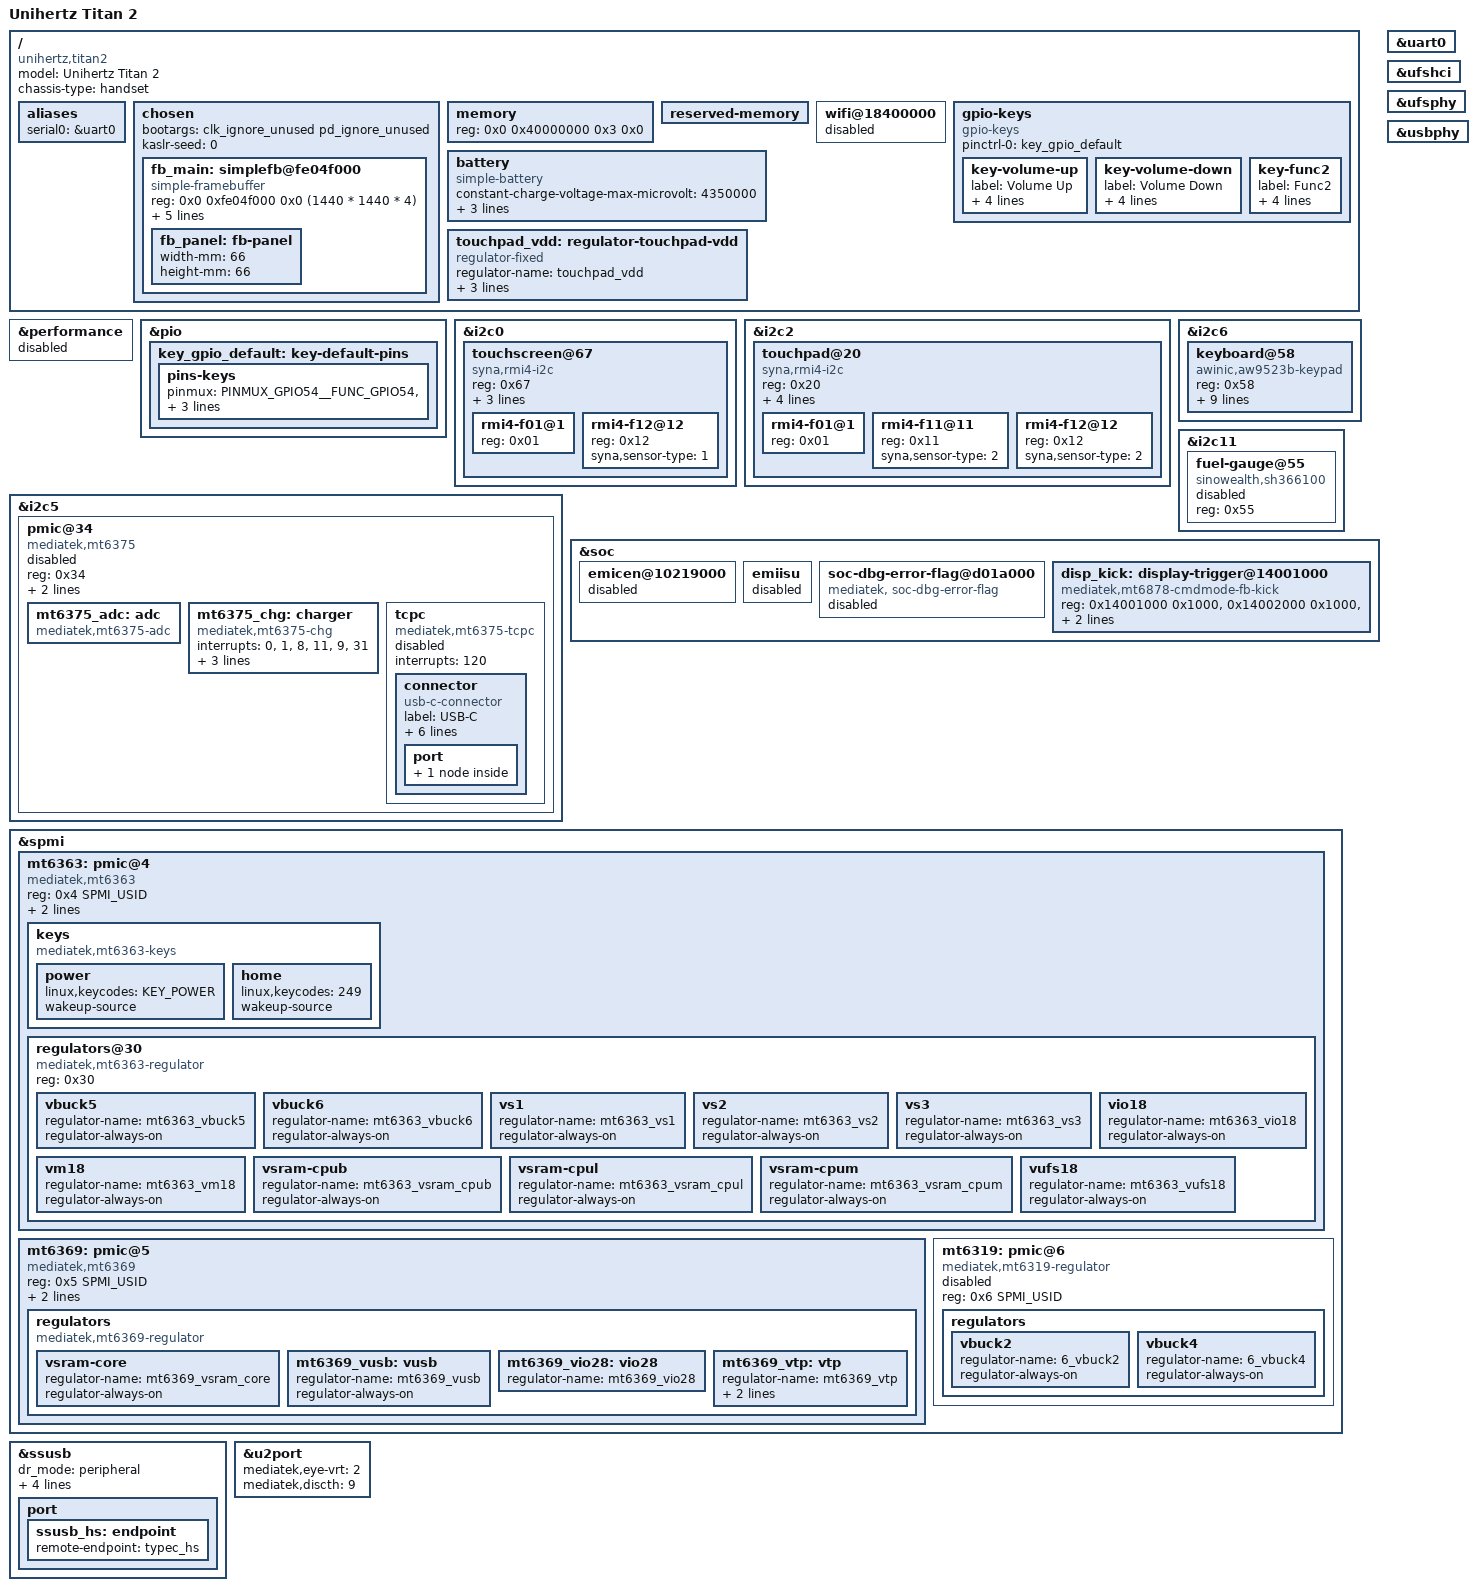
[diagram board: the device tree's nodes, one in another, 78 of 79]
// SPDX-License-Identifier: (GPL-2.0-only OR MIT)
/*
 * Unihertz Titan 2 (MediaTek MT6878 / Dimensity 7300)
 *
 * Copyright (c) 2026 serlk <22211586+Serlk@users.noreply.github.com>
 *
 * Booted by the stock LK from slot B; LK fills /chosen, memory and the
 * reserved-memory carveouts at boot. Values below are from the DT the
 * stock LK passes to Android (V01.00.14).
 */

/dts-v1/;
#include "mt6878.dtsi"
#include <dt-bindings/gpio/gpio.h>
#include <dt-bindings/iio/adc/mediatek,mt6375-adc.h>
#include <dt-bindings/input/input.h>
#include <dt-bindings/interrupt-controller/irq.h>
#include <dt-bindings/spmi/spmi.h>
#include <dt-bindings/usb/pd.h>

/ {
	model = "Unihertz Titan 2";
	chassis-type = "handset";
	compatible = "unihertz,titan2", "mediatek,mt6878";

	#address-cells = <2>;
	#size-cells = <2>;

	aliases {
		serial0 = &uart0;
	};

	chosen {
		bootargs = "clk_ignore_unused pd_ignore_unused";
		/* LK fills it from its TRNG, but only when the property exists */
		kaslr-seed = /bits/ 64 <0>;
		#address-cells = <2>;
		#size-cells = <2>;
		ranges;

		/*
		 * Main display (A61QWERTY46, 1440x1440) as left by LK:
		 * atag,videolfb fb_base 0xfe04f000, 59.92 Hz. Format and stride
		 * still to be confirmed on the device.
		 */
		fb_main: simplefb@fe04f000 {
			compatible = "simple-framebuffer";
			reg = <0x0 0xfe04f000 0x0 (1440 * 1440 * 4)>;
			width = <1440>;
			height = <1440>;
			stride = <(1440 * 4)>;
			format = "a8r8g8b8";
			panel = <&fb_panel>;

			fb_panel: fb-panel {
				width-mm = <66>;
				height-mm = <66>;
			};
		};
	};

	memory {
		device_type = "memory";
		/* 12 GiB; LK rewrites this node */
		reg = <0x0 0x40000000 0x3 0x0>;
	};

	/*
	 * The stock LK adds ~47 mblock-* carveouts here itself (ATF, TEE, modem,
	 * pstore, framebuffer, ...); static entries would overlap them. Start
	 * from an empty node instead of the SoC's static list.
	 */
	/delete-node/ reserved-memory;
	reserved-memory {
		#address-cells = <2>;
		#size-cells = <2>;
		ranges;
	};

	/*
	 * Nodes the stock LK requires when it completes the device tree
	 * (titan2-docs: docs/lk-boot-requirements.md);
	 * without them LK asserts or panics before starting the kernel.
	 * LK writes the Wi-Fi carveout into /wifi as memory-region.
	 */
	wifi@18400000 {
		status = "disabled";
	};

	gpio-keys {
		compatible = "gpio-keys";
		pinctrl-0 = <&key_gpio_default>;
		pinctrl-names = "default";

		key-volume-up {
			label = "Volume Up";
			linux,code = <KEY_VOLUMEUP>;
			gpios = <&pio 54 GPIO_ACTIVE_LOW>;
			debounce-interval = <30>;
			wakeup-source;
		};

		key-volume-down {
			label = "Volume Down";
			linux,code = <KEY_VOLUMEDOWN>;
			gpios = <&pio 55 GPIO_ACTIVE_LOW>;
			debounce-interval = <30>;
			wakeup-source;
		};

		/*
		 * Programmable side key "Func2" (as the GPL v2 module gpio_key.ko
		 * shipped with Titan 2 V01.00.14: GPIO73,
		 * both edges, low = pressed, scan code 250, 200 us EINT debounce).
		 */
		key-func2 {
			label = "Func2";
			linux,code = <250>;
			gpios = <&pio 73 GPIO_ACTIVE_LOW>;
			debounce-interval = <10>;
			wakeup-source;
		};
	};

	/*
	 * Li-ion pack (titan2-docs: docs/hardware). The charge voltage is the
	 * stock one: mtk_charger battery_cv 4.45 V, the MT6375 CV field reads
	 * 0x37 (4450 mV) in stock runtime logs. The current is a first-stage
	 * cap, below the stock 1.2 A (SDP) / 2.05 A (DCP); termination and
	 * the 0..50 degC charging window are the stock DT values.
	 *
	 * First stage: 4.35 V, what LK itself programs before the kernel, until
	 * charging has been watched on the device; the stock 4.45 V comes later.
	 */
	battery: battery {
		compatible = "simple-battery";
		constant-charge-voltage-max-microvolt = <4350000>;
		constant-charge-current-max-microamp = <1000000>;
		charge-term-current-microamp = <300000>;
		operating-range-celsius = <0 50>;
	};

	/*
	 * Power switch of the keyboard touchpad (stock touch_pad,pwr-gpio,
	 * GPIO59, high = on; the touchpad's GPL module of Titan 2 V01.00.14
	 * waits 20 ms before reset).
	 */
	touchpad_vdd: regulator-touchpad-vdd {
		compatible = "regulator-fixed";
		regulator-name = "touchpad_vdd";
		gpio = <&pio 59 GPIO_ACTIVE_HIGH>;
		enable-active-high;
		startup-delay-us = <20000>;
	};
};

/*
 * CPU DVFS stays with the frequencies LK left until it has been seen
 * working on the device: see mt6878-unihertz-titan2-dvfs.dts.
 */
&performance {
	status = "disabled";
};

&pio {
	key_gpio_default: key-default-pins {
		pins-keys {
			pinmux = <PINMUX_GPIO54__FUNC_GPIO54>,
				 <PINMUX_GPIO55__FUNC_GPIO55>;
			input-enable;
			bias-pull-up;
		};
	};
};

/*
 * Input devices from the stock DT (titan2-docs: docs/hardware). The keyboard and the
 * touchscreen take their supplies from the MT6369 on SPMI; a board without
 * SPMI has to disable them together with it.
 */

/*
 * Main touchscreen: Synaptics DSX/RMI4 (F12); facts from the GPL module
 * synaptics_tp.ko shipped with Titan 2 V01.00.14
 */
&i2c0 {
	#address-cells = <1>;
	#size-cells = <0>;

	/* The stock DT runs this bus at 400 kHz */
	touchscreen@67 {
		compatible = "syna,rmi4-i2c";
		reg = <0x67>;
		interrupts-extended = <&pio 7 IRQ_TYPE_LEVEL_LOW>;
		/* GPIO6 is routed as touch,reset-gpio but the factory driver never drives it */
		vdd-supply = <&mt6369_vtp>;
		syna,startup-delay-ms = <100>;

		#address-cells = <1>;
		#size-cells = <0>;

		rmi4-f01@1 {
			reg = <0x01>;
		};

		rmi4-f12@12 {
			reg = <0x12>;
			syna,sensor-type = <1>;
		};
	};
};

/*
 * Keyboard touchpad: Synaptics S1403, RMI4 (F11); facts from the GPL module
 * synaptics_1403_touch.ko shipped with Titan 2 V01.00.14
 */
&i2c2 {
	#address-cells = <1>;
	#size-cells = <0>;

	touchpad@20 {
		compatible = "syna,rmi4-i2c";
		reg = <0x20>;
		interrupts-extended = <&pio 75 IRQ_TYPE_LEVEL_LOW>;
		reset-gpios = <&pio 4 GPIO_ACTIVE_LOW>;
		vdd-supply = <&touchpad_vdd>;
		syna,reset-delay-ms = <120>;

		#address-cells = <1>;
		#size-cells = <0>;

		rmi4-f01@1 {
			reg = <0x01>;
		};

		rmi4-f11@11 {
			reg = <0x11>;
			syna,sensor-type = <2>;
		};

		rmi4-f12@12 {
			reg = <0x12>;
			syna,sensor-type = <2>;
		};
	};
};

/*
 * QWERTY keyboard: matrix on an AW9523B expander; facts from the GPL module
 * aw9523_key.ko shipped with Titan 2 V01.00.14
 */
&i2c6 {
	keyboard@58 {
		compatible = "awinic,aw9523b-keypad";
		reg = <0x58>;
		interrupts-extended = <&pio 12 IRQ_TYPE_LEVEL_LOW>;
		reset-gpios = <&pio 53 GPIO_ACTIVE_LOW>;
		vio-supply = <&mt6369_vio28>;
		label = "TitanKey";
		/* Stock input_port_mask 0x1ff and output_port_mask 0xfe00 */
		awinic,row-lines = <0 1 2 3 4 5 6 7 8>;
		awinic,column-lines = <9 10 11 12 13 14 15>;
		wakeup-source;

		/*
		 * The stock key_map[] as is: entry 7 * row + column. Duplicates and
		 * the F1/F10/F11/F13/arrows/VOLUMEUP/STOP..FIND entries probably have
		 * no key behind them. 251 is Fn, 253 Sym; Alt (KEY_RIGHTALT) is the
		 * only key on row 8, the stock "Alt wakes the screen" line.
		 */
		linux,keymap = <
					MATRIX_KEY(0, 0, KEY_Y)	/* 0 Y */
					MATRIX_KEY(0, 1, KEY_T)	/* 1 T */
					MATRIX_KEY(0, 2, KEY_G)	/* 2 G */
					MATRIX_KEY(0, 3, KEY_H)	/* 3 H */
					MATRIX_KEY(0, 4, KEY_SPACE)	/* 4 Space */
					MATRIX_KEY(0, 5, KEY_B)	/* 5 B */
					MATRIX_KEY(0, 6, KEY_F1)	/* 6 F1 */
					MATRIX_KEY(1, 0, KEY_U)	/* 7 U */
					MATRIX_KEY(1, 1, KEY_R)	/* 8 R */
					MATRIX_KEY(1, 2, KEY_F)	/* 9 F */
					MATRIX_KEY(1, 3, KEY_J)	/* 10 J */
					MATRIX_KEY(1, 4, KEY_V)	/* 11 V */
					MATRIX_KEY(1, 5, KEY_N)	/* 12 N */
					MATRIX_KEY(1, 6, KEY_U)	/* 13 U */
					MATRIX_KEY(2, 0, KEY_I)	/* 14 I */
					MATRIX_KEY(2, 1, KEY_E)	/* 15 E */
					MATRIX_KEY(2, 2, KEY_D)	/* 16 D */
					MATRIX_KEY(2, 3, KEY_K)	/* 17 K */
					MATRIX_KEY(2, 4, KEY_C)	/* 18 C */
					MATRIX_KEY(2, 5, KEY_M)	/* 19 M */
					MATRIX_KEY(2, 6, KEY_K)	/* 20 K */
					MATRIX_KEY(3, 0, KEY_O)	/* 21 O */
					MATRIX_KEY(3, 1, KEY_W)	/* 22 W */
					MATRIX_KEY(3, 2, KEY_S)	/* 23 S */
					MATRIX_KEY(3, 3, KEY_L)	/* 24 L */
					MATRIX_KEY(3, 4, KEY_X)	/* 25 X */
					MATRIX_KEY(3, 5, KEY_ENTER)	/* 26 ENTER */
					MATRIX_KEY(3, 6, KEY_F)	/* 27 F */
					MATRIX_KEY(4, 0, KEY_P)	/* 28 P */
					MATRIX_KEY(4, 1, KEY_Q)	/* 29 Q */
					MATRIX_KEY(4, 2, KEY_A)	/* 30 A */
					MATRIX_KEY(4, 3, KEY_BACKSPACE)	/* 31 DEL */
					MATRIX_KEY(4, 4, KEY_Z)	/* 32 Z */
					MATRIX_KEY(4, 5, KEY_Z)	/* 33 Z */
					MATRIX_KEY(4, 6, KEY_X)	/* 34 X */
					MATRIX_KEY(5, 0, KEY_LEFTSHIFT)	/* 35 SHIFT-L */
					MATRIX_KEY(5, 1, 253)	/* 36 AGUI_SYM */
					MATRIX_KEY(5, 2, KEY_BACK)	/* 37 BACK */
					MATRIX_KEY(5, 3, KEY_APPSELECT)	/* 38 MENU */
					MATRIX_KEY(5, 4, KEY_F10)	/* 39 F10 */
					MATRIX_KEY(5, 5, KEY_N)	/* 40 N */
					MATRIX_KEY(5, 6, KEY_M)	/* 41 M */
					MATRIX_KEY(6, 0, 251)	/* 42 FUNC3 */
					MATRIX_KEY(6, 1, KEY_DOWN)	/* 43 Down */
					MATRIX_KEY(6, 2, KEY_UP)	/* 44 Up */
					MATRIX_KEY(6, 3, KEY_ENTER)	/* 45 ENTER */
					MATRIX_KEY(6, 4, KEY_F11)	/* 46 F11 */
					MATRIX_KEY(6, 5, KEY_F13)	/* 47 F13 */
					MATRIX_KEY(6, 6, KEY_ALTERASE)	/* 48 ALT */
					MATRIX_KEY(7, 0, KEY_DOT)	/* 49 . */
					MATRIX_KEY(7, 1, KEY_LEFT)	/* 50 Left */
					MATRIX_KEY(7, 2, KEY_RIGHT)	/* 51 Right */
					MATRIX_KEY(7, 3, KEY_SPACE)	/* 52 Space */
					MATRIX_KEY(7, 4, KEY_VOLUMEUP)	/* 53 Volup */
					MATRIX_KEY(7, 5, KEY_STOP)	/* 54 KEY_STOP */
					MATRIX_KEY(7, 6, KEY_AGAIN)	/* 55 KEY_AGAIN */
					MATRIX_KEY(8, 0, KEY_RIGHTALT)	/* 56 SYM */
					MATRIX_KEY(8, 1, KEY_UNDO)	/* 57 UNDO */
					MATRIX_KEY(8, 2, KEY_FRONT)	/* 58 FRONT */
					MATRIX_KEY(8, 3, KEY_COPY)	/* 59 COPY */
					MATRIX_KEY(8, 4, KEY_OPEN)	/* 60 OPEN */
					MATRIX_KEY(8, 5, KEY_PASTE)	/* 61 PASTE */
					MATRIX_KEY(8, 6, KEY_FIND)	/* 62 FIND */
		>;
	};
};

/*
 * Charging (titan2-docs: docs/hardware). Neither bus is checked on mainline
 * yet, so both devices start disabled. The fuel gauge is read-only; enable
 * it first, then the charger, which only charges while the gauge reports a
 * battery temperature inside operating-range-celsius.
 */

/* MT6375 SubPMIC: charger, ADC, Type-C/PD; the stock DT runs this bus at 1 MHz */
&i2c5 {
	pmic@34 {
		compatible = "mediatek,mt6375";
		reg = <0x34>;
		interrupts-extended = <&pio 15 IRQ_TYPE_LEVEL_LOW>;
		interrupt-controller;
		#interrupt-cells = <1>;
		status = "disabled";

		mt6375_adc: adc {
			compatible = "mediatek,mt6375-adc";
			#io-channel-cells = <1>;
		};

		mt6375_chg: charger {
			compatible = "mediatek,mt6375-chg";
			interrupts = <0>, <1>, <8>, <11>, <9>, <31>;
			interrupt-names = "pwr_rdy", "detach", "vbus_ov",
					  "chg_tout", "chg_batov", "bc12_dn";
			io-channels = <&mt6375_adc MT6375_ADC_CHGVIN>,
				      <&mt6375_adc MT6375_ADC_IBUS>;
			io-channel-names = "vbus", "ibus";
			monitored-battery = <&battery>;
		};

		/*
		 * Type-C port. Sink only: the
		 * driver refuses to source VBUS (the OTG boost of the
		 * charger is not described at all) or VCONN. The only sink
		 * PDO is 5 V; the stock one is 5 V / 2 A as well, the stock
		 * PD charging algorithm raises it to 9 V later, which is not
		 * done here. Disabled until the port is checked on the
		 * device, step by step.
		 */
		tcpc {
			compatible = "mediatek,mt6375-tcpc";
			interrupts = <120>;
			interrupt-names = "pd_evt";
			status = "disabled";

			connector {
				compatible = "usb-c-connector";
				label = "USB-C";
				data-role = "device";
				power-role = "sink";
				self-powered;
				sink-pdos = <PDO_FIXED(5000, 2000,
						       PDO_FIXED_USB_COMM)>;
				op-sink-microwatt = <10000000>;

				port {
					typec_hs: endpoint {
						remote-endpoint = <&ssusb_hs>;
					};
				};
			};
		};
	};
};

/* SH366100 fuel gauge (bq27z561 commands, as the GPL v2 fauge.ko of V01.00.14 uses them) */
&i2c11 {
	#address-cells = <1>;
	#size-cells = <0>;

	fuel-gauge@55 {
		compatible = "sinowealth,sh366100";
		reg = <0x55>;
		status = "disabled";
	};
};

&soc {
	/* LK writes the EMI configuration into these */
	emicen@10219000 {
		status = "disabled";
	};

	emiisu {
		status = "disabled";
	};

	/* LK looks this node up by this exact compatible */
	soc-dbg-error-flag@d01a000 {
		compatible = "mediatek, soc-dbg-error-flag";
		status = "disabled";
	};

	/*
	 * The panel runs in DSI command mode: start a frame through LK's
	 * pipeline (mutex 0, OVL0, DSI0) after each simpledrm update.
	 */
	disp_kick: display-trigger@14001000 {
		compatible = "mediatek,mt6878-cmdmode-fb-kick";
		reg = <0x14001000 0x1000>,
		      <0x14002000 0x1000>,
		      <0x1401a000 0x1000>;
		reg-names = "mutex", "ovl", "dsi";
		mediatek,framebuffer = <&fb_main>;
	};
};

/*
 * PMICs as found on the stock DT. Only the rails the stock kernel keeps
 * always on and the SoC can not run without are described, as always-on,
 * without voltage limits: Linux never changes their voltage or mode, and
 * the regulator core never switches them off. Rails left out of the DT are
 * registered without constraints and are never touched either (e.g. the
 * UFS vcc/vccq supplies vemc and vufs12, which the stock kernel switches).
 */
&spmi {
	status = "okay";

	mt6363: pmic@4 {
		compatible = "mediatek,mt6363";
		reg = <0x4 SPMI_USID>;
		interrupts = <0x4 0 IRQ_TYPE_LEVEL_HIGH>;
		interrupt-controller;
		#interrupt-cells = <3>;
		#address-cells = <1>;
		#size-cells = <0>;

		keys {
			compatible = "mediatek,mt6363-keys";

			power {
				linux,keycodes = <KEY_POWER>;
				wakeup-source;
			};

			/* Programmable side key "Func1" (stock scan code 249) */
			home {
				linux,keycodes = <249>;
				wakeup-source;
			};
		};

		regulators@30 {
			compatible = "mediatek,mt6363-regulator";
			reg = <0x30>;

			/* CPU clusters (stock: proc1/proc3 and proc2 of the cpufreq node) */
			vbuck5 {
				regulator-name = "mt6363_vbuck5";
				regulator-always-on;
			};

			vbuck6 {
				regulator-name = "mt6363_vbuck6";
				regulator-always-on;
			};

			/* Input rails of the LDO groups */
			vs1 {
				regulator-name = "mt6363_vs1";
				regulator-always-on;
			};

			vs2 {
				regulator-name = "mt6363_vs2";
				regulator-always-on;
			};

			vs3 {
				regulator-name = "mt6363_vs3";
				regulator-always-on;
			};

			vio18 {
				regulator-name = "mt6363_vio18";
				regulator-always-on;
			};

			vm18 {
				regulator-name = "mt6363_vm18";
				regulator-always-on;
			};

			vsram-cpub {
				regulator-name = "mt6363_vsram_cpub";
				regulator-always-on;
			};

			vsram-cpul {
				regulator-name = "mt6363_vsram_cpul";
				regulator-always-on;
			};

			vsram-cpum {
				regulator-name = "mt6363_vsram_cpum";
				regulator-always-on;
			};

			/* 1.8V UFS/eMMC IO rail (stock: vqmmc of mmc0), always on in stock */
			vufs18 {
				regulator-name = "mt6363_vufs18";
				regulator-always-on;
			};
		};
	};

	mt6369: pmic@5 {
		compatible = "mediatek,mt6369";
		reg = <0x5 SPMI_USID>;
		interrupts = <0x5 0 IRQ_TYPE_LEVEL_HIGH>;
		interrupt-controller;
		#interrupt-cells = <3>;

		regulators {
			compatible = "mediatek,mt6369-regulator";

			vsram-core {
				regulator-name = "mt6369_vsram_core";
				regulator-always-on;
			};

			/* USB PHY 3.3V (stock: vusb33 of the USB controller) */
			mt6369_vusb: vusb {
				regulator-name = "mt6369_vusb";
				regulator-always-on;
			};

			/*
			 * Keyboard expander supply (stock mt6369_vio28-supply of
			 * aw9523b_led@58). Neither the stock DT nor its driver (the GPL
			 * module aw9523_key.ko) set a voltage: only switched on, at the level the PMIC comes up with.
			 */
			mt6369_vio28: vio28 {
				regulator-name = "mt6369_vio28";
			};

			/* Touchscreen supply, set to 2.8 V by the factory driver */
			mt6369_vtp: vtp {
				regulator-name = "mt6369_vtp";
				regulator-min-microvolt = <2800000>;
				regulator-max-microvolt = <2800000>;
			};
		};
	};

	/*
	 * MT6319 buck converter (MT6315 compatible), stock rails: vbuck1 ISP/CAM
	 * vcore, vbuck2 GPU, vbuck4 SoC vcore. The mainline MT6315 driver
	 * assumes a multi-phase vbuck1 for SID 6 and arms the power-off sequence
	 * on shutdown, unlike the factory driver: keep it off until checked.
	 */
	mt6319: pmic@6 {
		compatible = "mediatek,mt6319-regulator", "mediatek,mt6315-regulator";
		reg = <0x6 SPMI_USID>;
		status = "disabled";

		regulators {
			vbuck2 {
				regulator-name = "6_vbuck2";
				regulator-always-on;
			};

			vbuck4 {
				regulator-name = "6_vbuck4";
				regulator-always-on;
			};
		};
	};
};

/*
 * USB device mode only for now: the PHY forces the device role and VBUS
 * valid (mediatek,software-role-switch), as the stock kernel does through
 * mediatek,force-vbus.
 *
 * The role switch for the MT6375 Type-C port is described but inert while
 * dr_mode is "peripheral"; with dr_mode = "otg" the port manager drives
 * it, and "no role" falls back to the device role (no VBUS supply is
 * described, so a host role would not power the bus either).
 *
 * The SSUSB power domain is not referenced: the SCPSYS controller is still
 * disabled, and the domain is left on by the boot chain (the preloader
 * enumerates USB on every boot, LK only touches IPPC/MAC registers).
 */
&ssusb {
	dr_mode = "peripheral";
	maximum-speed = "high-speed";
	vusb33-supply = <&mt6369_vusb>;
	usb-role-switch;
	role-switch-default-mode = "peripheral";
	status = "okay";

	port {
		ssusb_hs: endpoint {
			remote-endpoint = <&typec_hs>;
		};
	};
};

&u2port {
	/* stock eye diagram and disconnect threshold tuning */
	mediatek,eye-vrt = <2>;
	mediatek,discth = <9>;
	status = "okay";
};

&uart0 {
	status = "okay";
};

&ufshci {
	status = "okay";
};

&ufsphy {
	status = "okay";
};

&usbphy {
	status = "okay";
};

#include "mt6878-titan2-lk-compat.dtsi"
